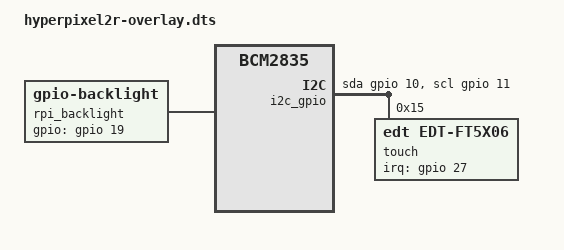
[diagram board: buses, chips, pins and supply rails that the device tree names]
/dts-v1/;
/plugin/;
/ {
    compatible = "brcm,bcm2835";

    fragment@0 {
        target = <&gpio>;
        __overlay__ {
            dpi18_pins: dpi18_pins {
                brcm,pins = <0 1 2 3 4 5 6 7 8 9 12 13 14 15 16 17 20 21 22 23 24 25>;
                brcm,function = <0x6>;
                brcm,pull = <0x0>;
            };
        };
    };
    fragment@1 {
        target-path = "/";
        __overlay__ {
            rpi_backlight: rpi_backlight {
                compatible = "gpio-backlight";
                gpios = <&gpio 19 0>;
                default-on;
                pinctrl-names = "default";
                pinctrl-0 = <&dpi18_pins>;
            };
        };
    };
    fragment@3 {
        target-path = "/";
        __overlay__ {
            i2c_gpio: i2c@0 {
                compatible = "i2c-gpio";
                gpios = <&gpio 10 0
                     &gpio 11 0
                    >;
                i2c-gpio,delay-us = <4>;
                #address-cells = <1>;
                #size-cells = <0>;
            };
        };
    };
    fragment@4 {
        target = <&i2c_gpio>;
        __overlay__ {
            #address-cells = <1>;
            #size-cells = <0>;
            touch: edt-ft5x06@15 {
                compatible = "edt,edt-ft5x06";
                reg = <0x15>;
                interrupt-parent = <&gpio>;
                interrupts = <27 2>;
                touchscreen-size-x = <480>;
                touchscreen-size-y = <480>;
                touchscreen-x-mm = <50>;
                touchscreen-y-mm = <50>;
            };
        };
    };
    __overrides__ {
        disable-i2c = <0>,"-3,-4";
        disable-touch = <0>,"-4";
    };
};
